# M4KQ register map
File version: 0.1
Registers are 32-bit, read-write, reset 0x0 unless marked. A register's access mark holds for its fields unless they carry their own. Offsets are from the block's base; [hi:lo] are bit positions; {n}, {i} and the like mark numbered series.

## PG — Port G
Base 0x400E0600
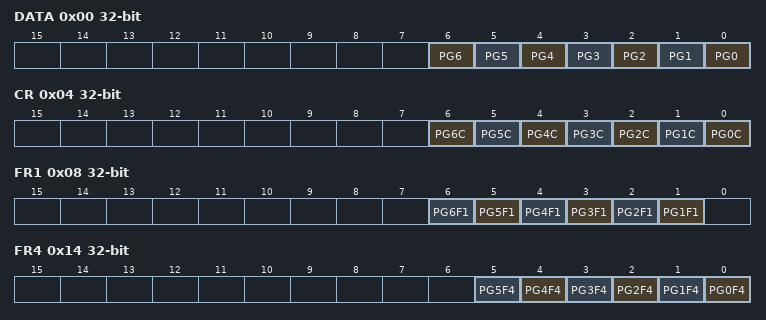
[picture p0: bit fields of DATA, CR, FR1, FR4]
0x00 DATA — Port G Data Register
  [n] PG{n} (n=0..6)
0x04 CR — Port G Output Control Register
  [n] PG{n}C (n=0..6)
0x08 FR1 — Port G Function Register 1
  [n] PG{n}F1 (n=1..6)
0x14 FR4 — Port G Function Register 4
  [n] PG{n}F4 (n=0..5)
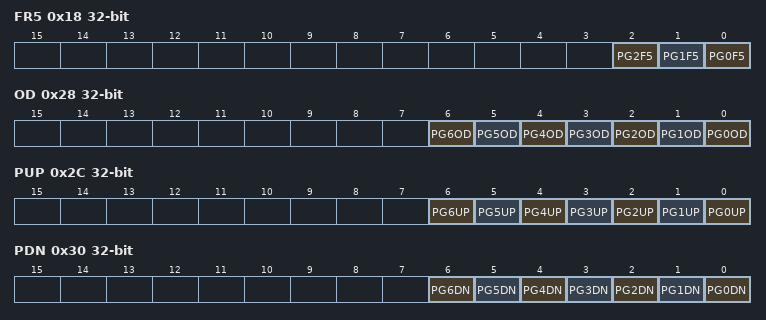
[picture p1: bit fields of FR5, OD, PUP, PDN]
0x18 FR5 — Port G Function Register 5
  [2] PG2F5, [1] PG1F5, [0] PG0F5
0x28 OD — Port G Open Drain Control Register
  [n] PG{n}OD (n=0..6)
0x2C PUP — Port G Pull-up Control Register
  [n] PG{n}UP (n=0..6)
0x30 PDN — Port G Pull-down Control Register
  [n] PG{n}DN (n=0..6)
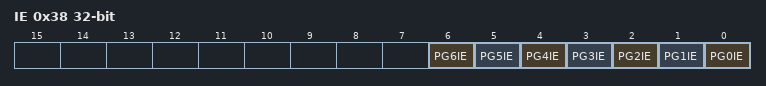
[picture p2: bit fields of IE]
0x38 IE — Port G Input Control Register
  [n] PG{n}IE (n=0..6)

## PH — Port H
Base 0x400E0700
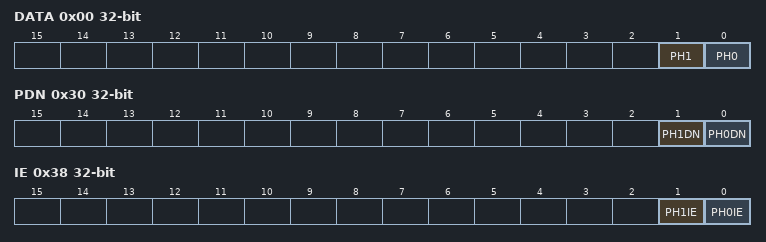
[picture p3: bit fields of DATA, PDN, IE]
0x00 DATA — Port H Data Register
  [1] PH1, [0] PH0
0x30 PDN — Port H Pull-down Control Register
  [1] PH1DN, [0] PH0DN
0x38 IE — Port H Input Control Register
  [1] PH1IE, [0] PH0IE

## PJ — Port J
Base 0x400E0800
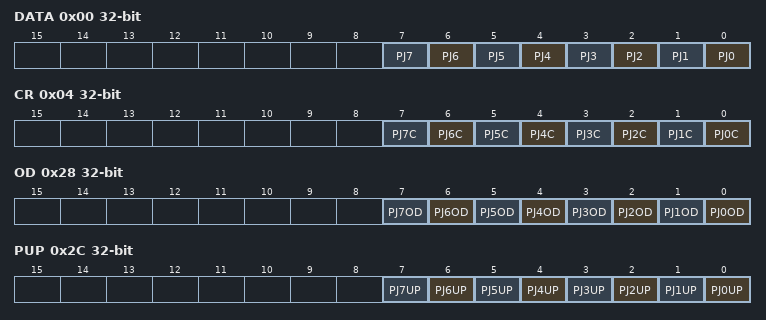
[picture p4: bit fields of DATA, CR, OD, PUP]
0x00 DATA — Port J Data Register
  [n] PJ{n} (n=0..7)
0x04 CR — Port J Output Control Register
  [n] PJ{n}C (n=0..7)
0x28 OD — Port J Open Drain Control Register
  [n] PJ{n}OD (n=0..7)
0x2C PUP — Port J Pull-up Control Register
  [n] PJ{n}UP (n=0..7)
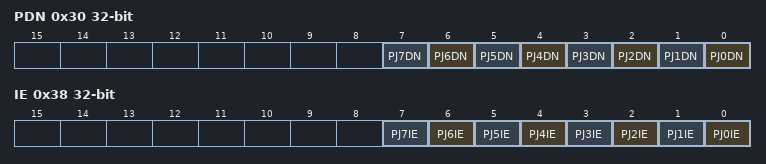
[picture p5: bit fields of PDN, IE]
0x30 PDN — Port J Pull-down Control Register
  [n] PJ{n}DN (n=0..7)
0x38 IE — Port J Input Control Register
  [n] PJ{n}IE (n=0..7)

## PK — Port K
Base 0x400E0900
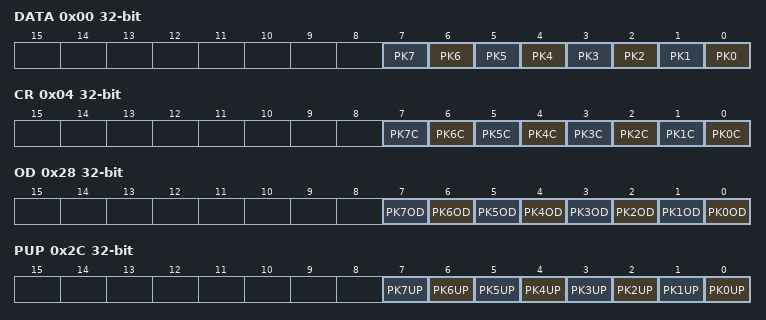
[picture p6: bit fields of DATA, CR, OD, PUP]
0x00 DATA — Port K Data Register
  [n] PK{n} (n=0..7)
0x04 CR — Port K Output Control Register
  [n] PK{n}C (n=0..7)
0x28 OD — Port K Open Drain Control Register
  [n] PK{n}OD (n=0..7)
0x2C PUP — Port K Pull-up Control Register
  [n] PK{n}UP (n=0..7)
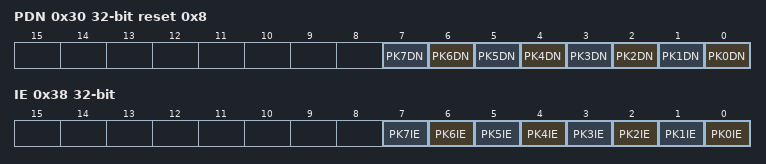
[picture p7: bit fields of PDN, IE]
0x30 PDN reset 0x8 — Port K Pull-down Control Register
  [n] PK{n}DN (n=0..7)
0x38 IE — Port K Input Control Register
  [n] PK{n}IE (n=0..7)

## PL — Port L
Base 0x400E0A00
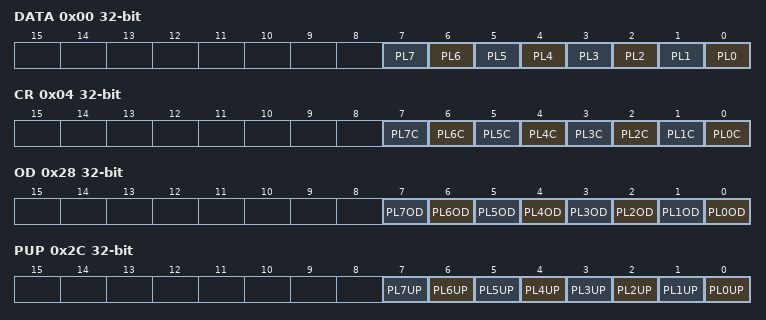
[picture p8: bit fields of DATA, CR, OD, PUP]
0x00 DATA — Port L Data Register
  [n] PL{n} (n=0..7)
0x04 CR — Port L Output Control Register
  [n] PL{n}C (n=0..7)
0x28 OD — Port L Open Drain Control Register
  [n] PL{n}OD (n=0..7)
0x2C PUP — Port L Pull-up Control Register
  [n] PL{n}UP (n=0..7)
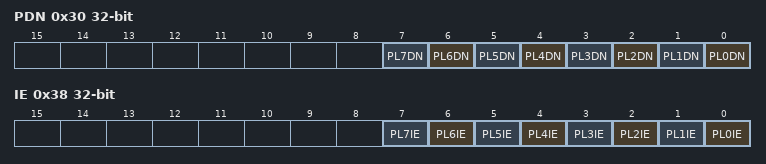
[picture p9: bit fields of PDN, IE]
0x30 PDN — Port L Pull-down Control Register
  [n] PL{n}DN (n=0..7)
0x38 IE — Port L Input Control Register
  [n] PL{n}IE (n=0..7)

## PM — Port M
Base 0x400E0B00
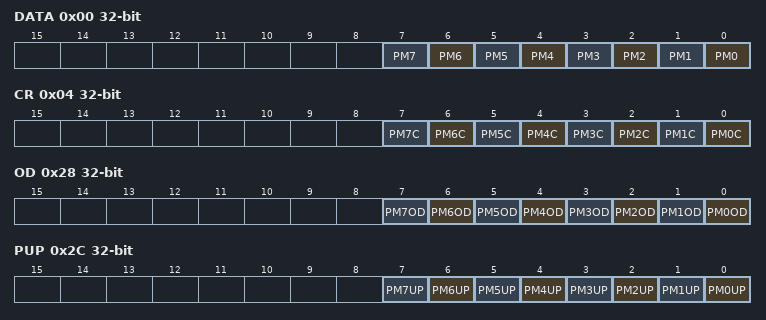
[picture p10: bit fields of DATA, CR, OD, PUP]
0x00 DATA — Port M Data Register
  [n] PM{n} (n=0..7)
0x04 CR — Port M Output Control Register
  [n] PM{n}C (n=0..7)
0x28 OD — Port M Open Drain Control Register
  [n] PM{n}OD (n=0..7)
0x2C PUP — Port M Pull-up Control Register
  [n] PM{n}UP (n=0..7)
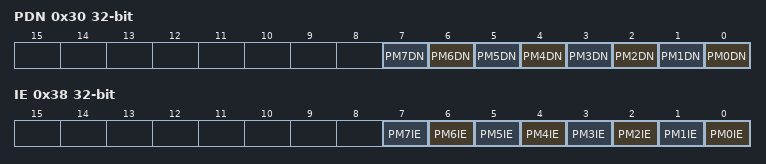
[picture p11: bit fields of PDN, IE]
0x30 PDN — Port M Pull-down Control Register
  [n] PM{n}DN (n=0..7)
0x38 IE — Port M Input Control Register
  [n] PM{n}IE (n=0..7)

## PN — Port N
Base 0x400E0C00
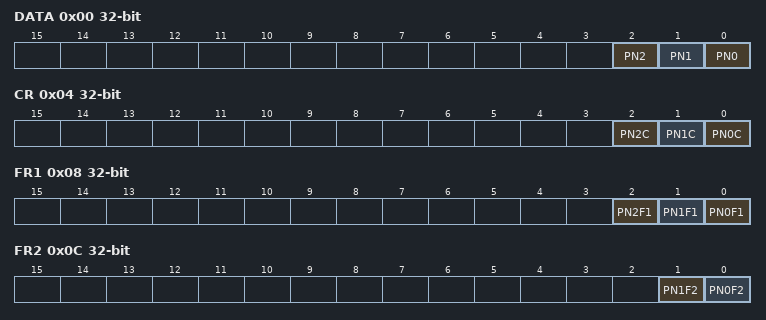
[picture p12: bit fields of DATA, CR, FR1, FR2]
0x00 DATA — Port N Data Register
  [2] PN2, [1] PN1, [0] PN0
0x04 CR — Port N Output Control Register
  [2] PN2C, [1] PN1C, [0] PN0C
0x08 FR1 — Port N Function Register 1
  [2] PN2F1, [1] PN1F1, [0] PN0F1
0x0C FR2 — Port N Function Register 2
  [1] PN1F2, [0] PN0F2
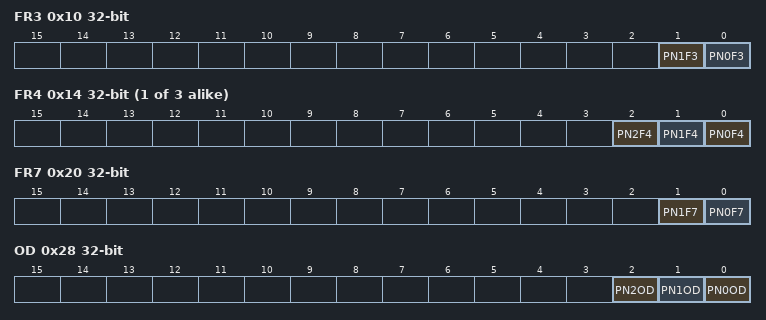
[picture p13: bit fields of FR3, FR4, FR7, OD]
0x10 FR3 — Port N Function Register 3
  [1] PN1F3, [0] PN0F3
{0x4+4i} FR{i} (i=4..6) — Port N Function Register {i}
  [2] PN2F{i}, [1] PN1F{i}, [0] PN0F{i}
0x20 FR7 — Port N Function Register 7
  [1] PN1F7, [0] PN0F7
0x28 OD — Port N Opend Drain Control Register
  [2] PN2OD, [1] PN1OD, [0] PN0OD
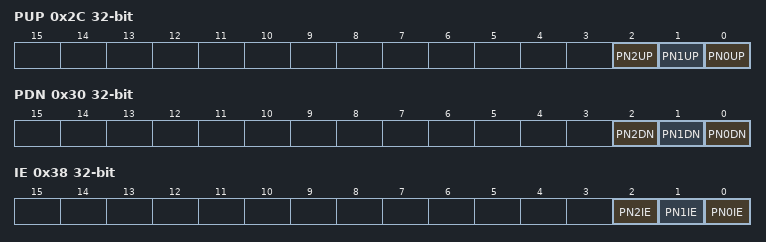
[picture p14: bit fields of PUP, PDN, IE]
0x2C PUP — Port N Pull-up Control Register
  [2] PN2UP, [1] PN1UP, [0] PN0UP
0x30 PDN — Port N Pull-down Control Register
  [2] PN2DN, [1] PN1DN, [0] PN0DN
0x38 IE — Port N Input Control Register
  [2] PN2IE, [1] PN1IE, [0] PN0IE

## PP — Port P
Base 0x400E0D00
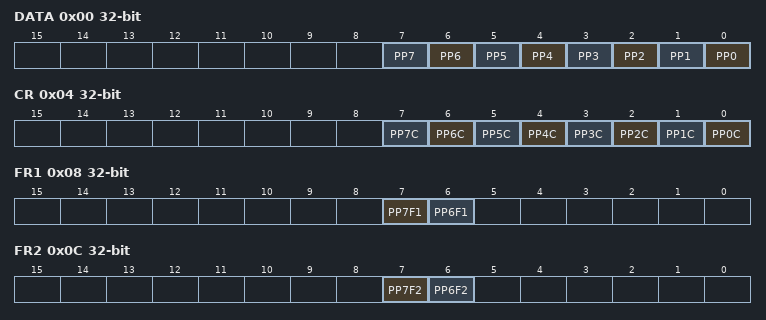
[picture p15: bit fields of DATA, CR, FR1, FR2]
0x00 DATA — Port P Data Register
  [n] PP{n} (n=0..7)
0x04 CR — Port P Output Control Register
  [n] PP{n}C (n=0..7)
0x08 FR1 — Port P Function Register 1
  [7] PP7F1, [6] PP6F1
0x0C FR2 — Port P Function Register 2
  [7] PP7F2, [6] PP6F2
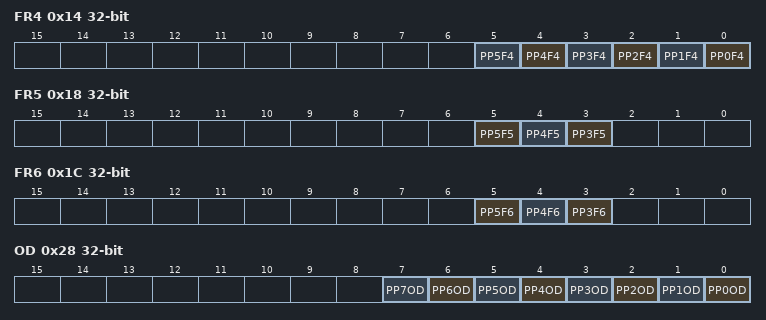
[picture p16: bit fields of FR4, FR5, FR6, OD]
0x14 FR4 — Port P Function Register 4
  [n] PP{n}F4 (n=0..5)
0x18 FR5 — Port P Function Register 5
  [5] PP5F5, [4] PP4F5, [3] PP3F5
0x1C FR6 — Port P Function Register 6
  [5] PP5F6, [4] PP4F6, [3] PP3F6
0x28 OD — Port P Open Drain Control Register
  [n] PP{n}OD (n=0..7)
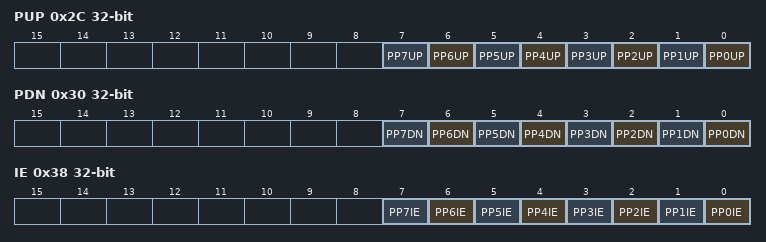
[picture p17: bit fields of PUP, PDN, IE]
0x2C PUP — Port P Pull-up Control Register
  [n] PP{n}UP (n=0..7)
0x30 PDN — Port P Pull-down Control Register
  [n] PP{n}DN (n=0..7)
0x38 IE — Port P Input Control Register
  [n] PP{n}IE (n=0..7)
